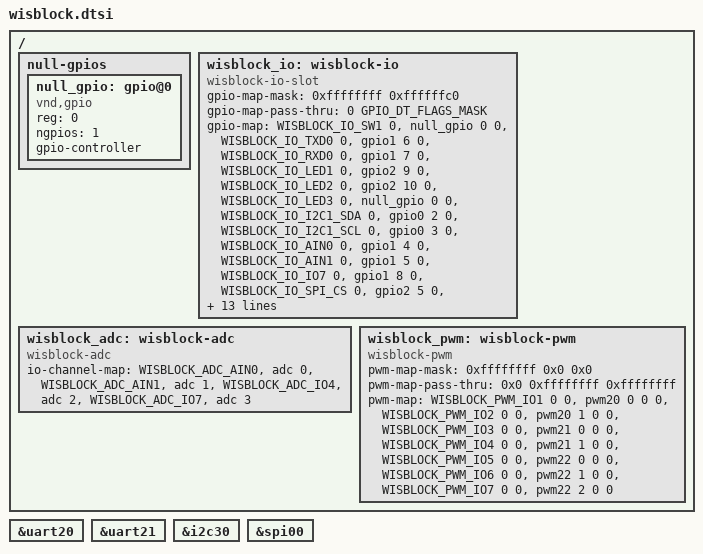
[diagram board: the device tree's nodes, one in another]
/*
 * SPDX-License-Identifier: Apache-2.0
 * Copyright (c) 2026 RAKwireless Technology Limited
 */

#include <zephyr/dt-bindings/gpio/wisblock-io-slot.h>
#include <zephyr/dt-bindings/adc/wisblock-adc.h>
#include <zephyr/dt-bindings/pwm/wisblock-pwm.h>

/ {
	null-gpios {
		#address-cells = <1>;
		#size-cells = <0>;

		null_gpio: gpio@0 {
			compatible = "vnd,gpio";
			status = "okay";
			reg = <0>;
			#gpio-cells = <2>;
			ngpios = <1>;
			gpio-controller;
		};
	};

	wisblock_io: wisblock-io {
		compatible = "wisblock-io-slot";
		#gpio-cells = <2>;
		gpio-map-mask = <0xffffffff 0xffffffc0>;
		gpio-map-pass-thru = <0 GPIO_DT_FLAGS_MASK>;
		gpio-map =
			<WISBLOCK_IO_SW1	0	&null_gpio	0	0>,
			<WISBLOCK_IO_TXD0	0	&gpio1	6	0>,
			<WISBLOCK_IO_RXD0	0	&gpio1	7	0>,
			<WISBLOCK_IO_LED1	0	&gpio2	9	0>,
			<WISBLOCK_IO_LED2	0	&gpio2	10	0>,
			<WISBLOCK_IO_LED3	0	&null_gpio	0	0>,
			<WISBLOCK_IO_I2C1_SDA	0	&gpio0	2	0>,
			<WISBLOCK_IO_I2C1_SCL	0	&gpio0	3	0>,
			<WISBLOCK_IO_AIN0	0	&gpio1	4	0>,
			<WISBLOCK_IO_AIN1	0	&gpio1	5	0>,
			<WISBLOCK_IO_IO7	0	&gpio1	8	0>,
			<WISBLOCK_IO_SPI_CS	0	&gpio2	5	0>,
			<WISBLOCK_IO_SPI_CLK	0	&gpio2	1	0>,
			<WISBLOCK_IO_SPI_MISO	0	&gpio2	4	0>,
			<WISBLOCK_IO_SPI_MOSI	0	&gpio2	2	0>,
			<WISBLOCK_IO_IO1	0	&gpio1	14	0>,
			<WISBLOCK_IO_IO2	0	&gpio2	0	0>,
			<WISBLOCK_IO_IO3	0	&gpio2	3	0>,
			<WISBLOCK_IO_IO4	0	&gpio2	6	0>,
			<WISBLOCK_IO_TXD1	0	&gpio2	8	0>,
			<WISBLOCK_IO_RXD1	0	&gpio2	7	0>,
			<WISBLOCK_IO_I2C2_SDA	0	&null_gpio	0	0>,
			<WISBLOCK_IO_I2C2_SCL	0	&null_gpio	0	0>,
			<WISBLOCK_IO_IO5	0	&gpio1	2	0>,
			<WISBLOCK_IO_IO6	0	&gpio1	3	0>;
	};

	wisblock_adc: wisblock-adc {
		compatible = "wisblock-adc";
		#io-channel-cells = <1>;
		io-channel-map =
			<WISBLOCK_ADC_AIN0	&adc	0>,
			<WISBLOCK_ADC_AIN1	&adc	1>,
			<WISBLOCK_ADC_IO4	&adc	2>,
			<WISBLOCK_ADC_IO7	&adc	3>;
	};

	wisblock_pwm: wisblock-pwm {
		compatible = "wisblock-pwm";
		#pwm-cells = <3>;
		pwm-map-mask = <0xffffffff 0x0 0x0>;
		pwm-map-pass-thru = <0x0 0xffffffff 0xffffffff>;
		pwm-map =
			<WISBLOCK_PWM_IO1	0	0	&pwm20	0	0	0>,
			<WISBLOCK_PWM_IO2	0	0	&pwm20	1	0	0>,
			<WISBLOCK_PWM_IO3	0	0	&pwm21	0	0	0>,
			<WISBLOCK_PWM_IO4	0	0	&pwm21	1	0	0>,
			<WISBLOCK_PWM_IO5	0	0	&pwm22	0	0	0>,
			<WISBLOCK_PWM_IO6	0	0	&pwm22	1	0	0>,
			<WISBLOCK_PWM_IO7	0	0	&pwm22	2	0	0>;
	};
};

wisblock_console: &uart20 {};

wisblock_uart0: &uart20 {};
wisblock_uart1: &uart21 {};
wisblock_i2c1: &i2c30 {};
wisblock_spi: &spi00 {};
